# SF32LB57x register map
File version: 1.0
CPU: CM33 r0p1, little endian, MPU, FPU, 3 interrupt priority bits
Registers are 32-bit, read-write, reset 0x0 unless marked. A register's access mark holds for its fields unless they carry their own. Offsets are from the block's base; [hi:lo] are bit positions; 'fields as' and 'values as' point back to an identical list.

## LPSYS_SECU
Base 0x40007000
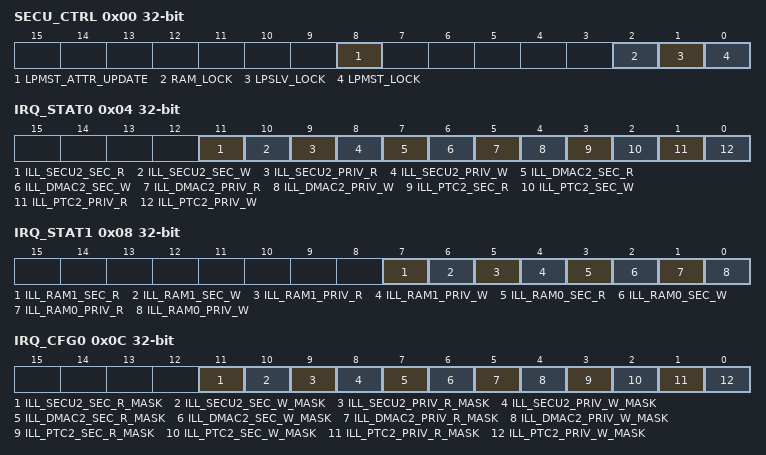
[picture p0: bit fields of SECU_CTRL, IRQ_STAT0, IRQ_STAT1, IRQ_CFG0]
0x00 SECU_CTRL
  [8] LPMST_ATTR_UPDATE, [2] RAM_LOCK, [1] LPSLV_LOCK, [0] LPMST_LOCK
0x04 IRQ_STAT0
  [11] ILL_SECU2_SEC_R
  [10] ILL_SECU2_SEC_W
  [9] ILL_SECU2_PRIV_R
  [8] ILL_SECU2_PRIV_W
  [7] ILL_DMAC2_SEC_R
  [6] ILL_DMAC2_SEC_W
  [5] ILL_DMAC2_PRIV_R
  [4] ILL_DMAC2_PRIV_W
  [3] ILL_PTC2_SEC_R
  [2] ILL_PTC2_SEC_W
  [1] ILL_PTC2_PRIV_R
  [0] ILL_PTC2_PRIV_W — write 1 to clear the interrupt
0x08 IRQ_STAT1
  [7] ILL_RAM1_SEC_R, [6] ILL_RAM1_SEC_W, [5] ILL_RAM1_PRIV_R, [4] ILL_RAM1_PRIV_W, [3] ILL_RAM0_SEC_R, [2] ILL_RAM0_SEC_W, [1] ILL_RAM0_PRIV_R, [0] ILL_RAM0_PRIV_W
0x0C IRQ_CFG0
  [11] ILL_SECU2_SEC_R_MASK
  [10] ILL_SECU2_SEC_W_MASK
  [9] ILL_SECU2_PRIV_R_MASK
  [8] ILL_SECU2_PRIV_W_MASK
  [7] ILL_DMAC2_SEC_R_MASK
  [6] ILL_DMAC2_SEC_W_MASK
  [5] ILL_DMAC2_PRIV_R_MASK
  [4] ILL_DMAC2_PRIV_W_MASK
  [3] ILL_PTC2_SEC_R_MASK
  [2] ILL_PTC2_SEC_W_MASK
  [1] ILL_PTC2_PRIV_R_MASK
  [0] ILL_PTC2_PRIV_W_MASK — 0: mask the interrupt
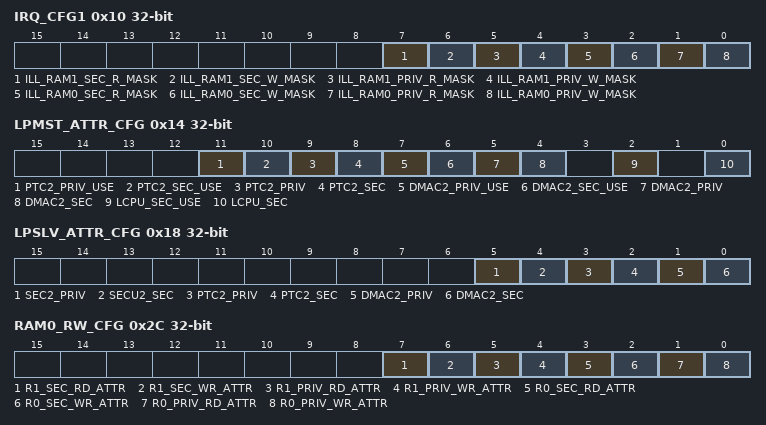
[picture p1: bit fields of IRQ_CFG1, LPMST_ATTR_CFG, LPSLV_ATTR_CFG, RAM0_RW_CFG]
0x10 IRQ_CFG1
  [7] ILL_RAM1_SEC_R_MASK, [6] ILL_RAM1_SEC_W_MASK, [5] ILL_RAM1_PRIV_R_MASK, [4] ILL_RAM1_PRIV_W_MASK, [3] ILL_RAM0_SEC_R_MASK, [2] ILL_RAM0_SEC_W_MASK, [1] ILL_RAM0_PRIV_R_MASK, [0] ILL_RAM0_PRIV_W_MASK
0x14 LPMST_ATTR_CFG
  [11] PTC2_PRIV_USE — set 1 to use ptc2_priv as ptc2 master interface priviledge attribute
  [10] PTC2_SEC_USE — set 1 to use ptc2_sec as ptc2 master interface priviledge attribute
  [9] PTC2_PRIV — priviledge attribute 0: non priviledge 1: priviledge
  [8] PTC2_SEC — secure attribute 0: non secure 1: secure
  [7] DMAC2_PRIV_USE — set 1 to use dmac2_priv as dmac2 master interface priviledge attribute
  [6] DMAC2_SEC_USE — set 1 to use dmac2_sec as dmac2 master interface priviledge attribute
  [5] DMAC2_PRIV — priviledge attribute 0: non priviledge 1: priviledge
  [4] DMAC2_SEC — secure attribute 0: non secure 1: secure
  [2] LCPU_SEC_USE — set 1 to use lcpu_sec as lcpu master interface priviledge attribute
  [0] LCPU_SEC — secure attribute 0: non secure 1: secure
0x18 LPSLV_ATTR_CFG
  [5] SEC2_PRIV — priviledge attribute 0: non priviledge 1: priviledge
  [4] SECU2_SEC — secure attribute 0: non secure 1: secure
  [3] PTC2_PRIV — priviledge attribute 0: non priviledge 1: priviledge
  [2] PTC2_SEC — secure attribute 0: non secure 1: secure
  [1] DMAC2_PRIV — priviledge attribute 0: non priviledge 1: priviledge
  [0] DMAC2_SEC — secure attribute 0: non secure 1: secure
0x1C RAM0_R0_CFG0
  [31:2] ST_ADDR
0x20 RAM0_R0_CFG1
  [31:2] END_ADDR
0x24 RAM0_R1_CFG0
  [31:2] ST_ADDR
0x28 RAM0_R1_CFG1
  [31:2] END_ADDR
0x2C RAM0_RW_CFG
  [7] R1_SEC_RD_ATTR — region1 secure read attribute
  [6] R1_SEC_WR_ATTR — region1 secure write attribute
  [5] R1_PRIV_RD_ATTR — region1 priviledge read attribute
  [4] R1_PRIV_WR_ATTR — region1 priviledge write attribute
  [3] R0_SEC_RD_ATTR — region0 secure read attribute
  [2] R0_SEC_WR_ATTR — region0 secure write attribute
  [1] R0_PRIV_RD_ATTR — region0 priviledge read attribute
  [0] R0_PRIV_WR_ATTR — region0 priviledge write attribute
0x30 RAM1_R0_CFG0
  [31:2] ST_ADDR
0x34 RAM1_R0_CFG1
  [31:2] END_ADDR
0x38 RAM1_R1_CFG0
  [31:2] ST_ADDR
0x3C RAM1_R1_CFG1
  [31:2] END_ADDR
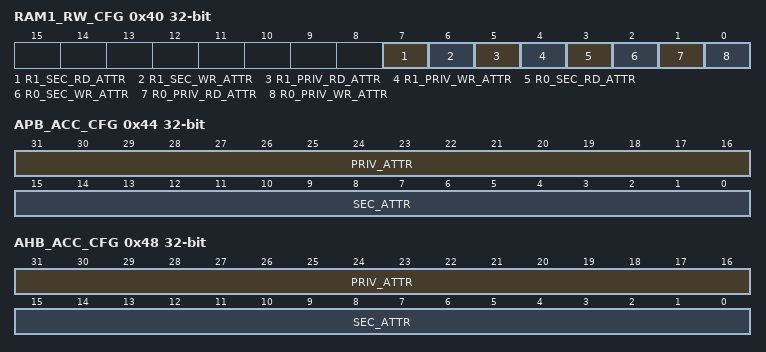
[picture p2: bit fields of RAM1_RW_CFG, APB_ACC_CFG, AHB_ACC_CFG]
0x40 RAM1_RW_CFG
  fields as RAM0_RW_CFG
0x44 APB_ACC_CFG
  [31:16] PRIV_ATTR — write 1 to set priviledge access check
  [15:0] SEC_ATTR — write 1 to set secure access check bit0: GPIO2 reg bit2: RFC reg bit4: BT PHY reg bit5: CRC2 reg bit9: BT MAC reg other: reserved
0x48 AHB_ACC_CFG
  [31:16] PRIV_ATTR — write 1 to set priviledge access check
  [15:0] SEC_ATTR — write 1 to set secure access check bit0: RCC2 reg bit1: DMAC2 reg bit2: MAILBOX2 reg bit3: PINMUX2 reg bit4: PATCH reg bit5: USART4 reg bit6: USART5 reg bit7: SECU2 reg bit9: BTIM3 reg bit10: BTIM4 reg bit12: PTC2 reg bit15: SYSCFG2 reg other: reserved
